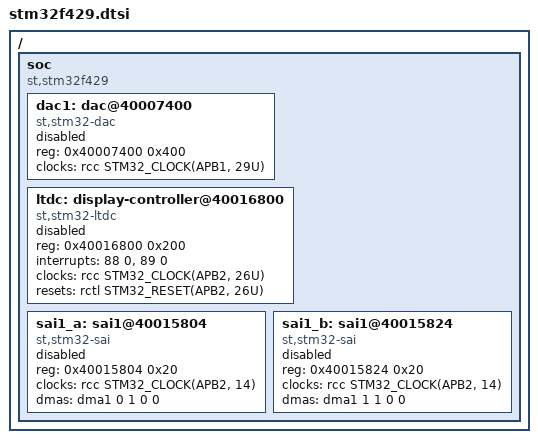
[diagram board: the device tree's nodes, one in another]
/*
 * Copyright (c) 2017, 2020 Linaro Limited
 * Copyright (c) 2025 Mario Paja <mariopaja@hotmail.com>
 *
 * SPDX-License-Identifier: Apache-2.0
 */

#include <st/f4/stm32f427.dtsi>
#include <zephyr/dt-bindings/display/panel.h>

/ {
	soc {
		compatible = "st,stm32f429", "st,stm32f4", "simple-bus";

		dac1: dac@40007400 {
			compatible = "st,stm32-dac";
			reg = <0x40007400 0x400>;
			clocks = <&rcc STM32_CLOCK(APB1, 29U)>;
			status = "disabled";
			#io-channel-cells = <1>;
		};

		ltdc: display-controller@40016800 {
			compatible = "st,stm32-ltdc";
			reg = <0x40016800 0x200>;
			interrupts = <88 0>, <89 0>;
			interrupt-names = "ltdc", "ltdc_er";
			clocks = <&rcc STM32_CLOCK(APB2, 26U)>;
			resets = <&rctl STM32_RESET(APB2, 26U)>;
			status = "disabled";
		};

		sai1_a: sai1@40015804 {
			compatible = "st,stm32-sai";
			#address-cells = <1>;
			#size-cells = <0>;
			reg = <0x40015804 0x20>;
			clocks = <&rcc STM32_CLOCK(APB2, 14)>;
			dmas = <&dma1 0 1 0 0>;
			status = "disabled";
		};

		sai1_b: sai1@40015824 {
			compatible = "st,stm32-sai";
			#address-cells = <1>;
			#size-cells = <0>;
			reg = <0x40015824 0x20>;
			clocks = <&rcc STM32_CLOCK(APB2, 14)>;
			dmas = <&dma1 1 1 0 0>;
			status = "disabled";
		};
	};
};
